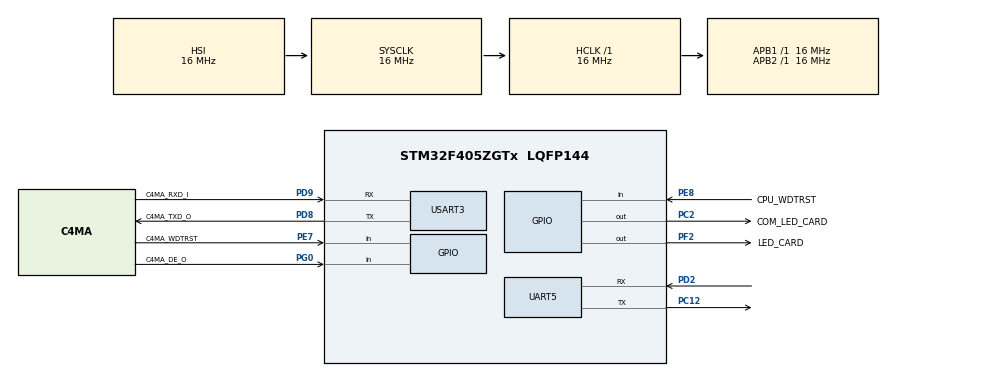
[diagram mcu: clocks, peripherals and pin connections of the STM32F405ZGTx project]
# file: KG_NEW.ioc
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FREERTOS.INCLUDE_vTaskDelete=1
FREERTOS.Tasks01=defaultTask,24,128,StartDefaultTask,Default,NULL,Dynamic,NULL,NULL;LED_Task,8,128,LED_Blink,Default,NULL,Dynamic,NULL,NULL
FREERTOS.configLIBRARY_LOWEST_INTERRUPT_PRIORITY=3
FREERTOS.configLIBRARY_MAX_SYSCALL_INTERRUPT_PRIORITY=3
FREERTOS.configUSE_NEWLIB_REENTRANT=1
Mcu.Family=STM32F4
Mcu.Name=STM32F405ZGTx
Mcu.Package=LQFP144
NVIC.PriorityGroup=NVIC_PRIORITYGROUP_4
NVIC.TIM3_IRQn=true\:15\:0\:false\:false\:true\:false\:false\:true\:true
NVIC.TimeBase=TIM3_IRQn
NVIC.TimeBaseIP=TIM3
NVIC.USART3_IRQn=true\:3\:0\:false\:false\:true\:true\:true\:true\:true
PC12.Mode=Asynchronous
PC12.Signal=UART5_TX
PC2.GPIO_Label=COM_LED_CARD
PC2.Signal=GPIO_Output
PD2.Mode=Asynchronous
PD2.Signal=UART5_RX
PD8.GPIO_Label=C4MA_TXD_O
PD8.Mode=Asynchronous
PD8.Signal=USART3_TX
PD9.GPIO_Label=C4MA_RXD_I
PD9.Mode=Asynchronous
PD9.Signal=USART3_RX
PE7.GPIO_Label=C4MA_WDTRST
PE7.Signal=GPIO_Input
PE8.GPIO_Label=CPU_WDTRST
PE8.Signal=GPIO_Input
PF2.GPIO_Label=LED_CARD
PF2.Signal=GPIO_Output
PG0.GPIO_Label=C4MA_DE_O
PG0.Signal=GPIO_Input
PH0-OSC_IN.Mode=HSE-External-Oscillator
PH0-OSC_IN.Signal=RCC_OSC_IN
PH1-OSC_OUT.Mode=HSE-External-Oscillator
PH1-OSC_OUT.Signal=RCC_OSC_OUT
ProjectManager.HeapSize=0x200
ProjectManager.StackSize=0x400
ProjectManager.TargetToolchain=STM32CubeIDE
RCC.48MHZClocksFreq_Value=75000000
RCC.AHBFreq_Value=16000000
RCC.APB1Freq_Value=16000000
RCC.APB2Freq_Value=16000000
RCC.CortexFreq_Value=16000000
RCC.HSE_VALUE=25000000
RCC.HSI_VALUE=16000000
RCC.LSE_VALUE=32768
RCC.PLLSourceVirtual=RCC_PLLSOURCE_HSE
RCC.SYSCLKFreq_VALUE=16000000
RCC.VCOOutputFreq_Value=300000000
UART5.VirtualMode=Asynchronous
USART3.VirtualMode=VM_ASYNC
VP_FREERTOS_VS_CMSIS_V2.Mode=CMSIS_V2
VP_SYS_VS_tim3.Mode=TIM3
board=custom

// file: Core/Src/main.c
/* USER CODE BEGIN Header */
/**
  ******************************************************************************
  * @file           : main.c
  * @brief          : Main program body
  ******************************************************************************
  * @attention
  *
  * Copyright (c) 2022 STMicroelectronics.
  * All rights reserved.
  *
  * This software is licensed under terms that can be found in the LICENSE file
  * in the root directory of this software component.
  * If no LICENSE file comes with this software, it is provided AS-IS.
  *
  ******************************************************************************
  */
/* USER CODE END Header */
#include "main.h"
#include "cmsis_os.h"
#include "usart.h"
#include "gpio.h"

void SystemClock_Config(void);
void MX_FREERTOS_Init(void);

int main(void)
{

  /* MCU Configuration--------------------------------------------------------*/

  /* Reset of all peripherals, Initializes the Flash interface and the Systick. */
  HAL_Init();

  /* Configure the system clock */
  SystemClock_Config();

  /* Initialize all configured peripherals */
  MX_GPIO_Init();
  MX_UART5_Init();
  MX_USART3_UART_Init();

  /* Init scheduler */
  osKernelInitialize();  /* Call init function for freertos objects (in freertos.c) */
  MX_FREERTOS_Init();

  /* Start scheduler */
  osKernelStart();

  /* We should never get here as control is now taken by the scheduler */
  /* Infinite loop */
  while (1)
  {

    /* USER CODE BEGIN 3 */
//	  HAL_GPIO_TogglePin (LED_CARD_GPIO_Port, LED_CARD_Pin);
//	  HAL_Delay (2000);   /* Insert delay 100 ms */
  }
  /* USER CODE END 3 */
}

void SystemClock_Config(void)
{
  RCC_OscInitTypeDef RCC_OscInitStruct = {0};
  RCC_ClkInitTypeDef RCC_ClkInitStruct = {0};

  /** Configure the main internal regulator output voltage
  */
  __HAL_RCC_PWR_CLK_ENABLE();
  __HAL_PWR_VOLTAGESCALING_CONFIG(PWR_REGULATOR_VOLTAGE_SCALE1);

  /** Initializes the RCC Oscillators according to the specified parameters
  * in the RCC_OscInitTypeDef structure.
  */
  RCC_OscInitStruct.OscillatorType = RCC_OSCILLATORTYPE_HSI;
  RCC_OscInitStruct.HSIState = RCC_HSI_ON;
  RCC_OscInitStruct.HSICalibrationValue = RCC_HSICALIBRATION_DEFAULT;
  RCC_OscInitStruct.PLL.PLLState = RCC_PLL_NONE;
  if (HAL_RCC_OscConfig(&RCC_OscInitStruct) != HAL_OK)
  {
    Error_Handler();
  }

  /** Initializes the CPU, AHB and APB buses clocks
  */
  RCC_ClkInitStruct.ClockType = RCC_CLOCKTYPE_HCLK|RCC_CLOCKTYPE_SYSCLK
                              |RCC_CLOCKTYPE_PCLK1|RCC_CLOCKTYPE_PCLK2;
  RCC_ClkInitStruct.SYSCLKSource = RCC_SYSCLKSOURCE_HSI;
  RCC_ClkInitStruct.AHBCLKDivider = RCC_SYSCLK_DIV1;
  RCC_ClkInitStruct.APB1CLKDivider = RCC_HCLK_DIV1;
  RCC_ClkInitStruct.APB2CLKDivider = RCC_HCLK_DIV1;

  if (HAL_RCC_ClockConfig(&RCC_ClkInitStruct, FLASH_LATENCY_0) != HAL_OK)
  {
    Error_Handler();
  }
}

void HAL_TIM_PeriodElapsedCallback(TIM_HandleTypeDef *htim)
{
  if (htim->Instance == TIM3) {
    HAL_IncTick();
  }
}

void Error_Handler(void)
{
  __disable_irq();
  while (1)
  {
  }
}

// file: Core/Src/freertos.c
/* USER CODE BEGIN Header */
/**
  ******************************************************************************
  * File Name          : freertos.c
  * Description        : Code for freertos applications
  ******************************************************************************
  * @attention
  *
  * Copyright (c) 2022 STMicroelectronics.
  * All rights reserved.
  *
  * This software is licensed under terms that can be found in the LICENSE file
  * in the root directory of this software component.
  * If no LICENSE file comes with this software, it is provided AS-IS.
  *
  ******************************************************************************
  */
/* USER CODE END Header */

#include "FreeRTOS.h"
#include "task.h"
#include "main.h"
#include "cmsis_os.h"

/* Definitions for defaultTask */
osThreadId_t defaultTaskHandle;
const osThreadAttr_t defaultTask_attributes = {
  .name = "defaultTask",
  .stack_size = 128 * 4,
  .priority = (osPriority_t) osPriorityNormal,
};
/* Definitions for LED_Task */
osThreadId_t LED_TaskHandle;
const osThreadAttr_t LED_Task_attributes = {
  .name = "LED_Task",
  .stack_size = 128 * 4,
  .priority = (osPriority_t) osPriorityLow,
};

void StartDefaultTask(void *argument);
void LED_Blink(void *argument);

void MX_FREERTOS_Init(void); /* (MISRA C 2004 rule 8.1) */

void MX_FREERTOS_Init(void) {

  /* Create the thread(s) */
  /* creation of defaultTask */
  defaultTaskHandle = osThreadNew(StartDefaultTask, NULL, &defaultTask_attributes);

  /* creation of LED_Task */
  LED_TaskHandle = osThreadNew(LED_Blink, NULL, &LED_Task_attributes);

}

void StartDefaultTask(void *argument)
{
  for(;;)
  {
    osDelay(1);
  }
}

void LED_Blink(void *argument)
{
  /* USER CODE BEGIN LED_Blink */
  /* Infinite loop */
  for(;;)
  {
	  HAL_GPIO_TogglePin (LED_CARD_GPIO_Port, LED_CARD_Pin);
	  osDelay(200);
  }
  /* USER CODE END LED_Blink */
}
